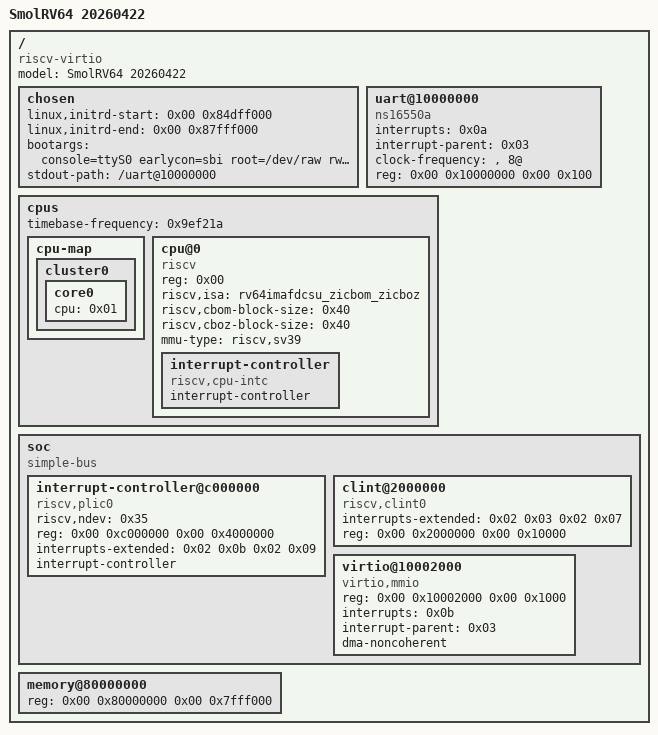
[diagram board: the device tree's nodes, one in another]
/dts-v1/;

/ {
	#address-cells = <0x02>;
	#size-cells = <0x02>;
	compatible = "riscv-virtio";
	model = "SmolRV64 20260422";

	chosen {
		linux,initrd-start = <0x00 0x84dff000>;
		linux,initrd-end = <0x00 0x87fff000>;
		bootargs = "console=ttyS0 earlycon=sbi root=/dev/raw rw ignore_loglevel";
		stdout-path = "/uart@10000000";
	};

	uart@10000000 {
		interrupts = <0x0a>;
		interrupt-parent = <0x03>;
		clock-frequency = "", "8@";
		reg = <0x00 0x10000000 0x00 0x100>;
		compatible = "ns16550a";
	};

	cpus {
		#address-cells = <0x01>;
		#size-cells = <0x00>;
		timebase-frequency = <0x9ef21a>;

		cpu-map {

			cluster0 {

				core0 {
					cpu = <0x01>;
				};
			};
		};

		cpu@0 {
			phandle = <0x01>;
			device_type = "cpu";
			reg = <0x00>;
			status = "okay";
			compatible = "riscv";
			riscv,isa = "rv64imafdcsu_zicbom_zicboz";
			riscv,cbom-block-size = <0x40>;
			riscv,cboz-block-size = <0x40>;
			mmu-type = "riscv,sv39";

			interrupt-controller {
				#interrupt-cells = <0x01>;
				interrupt-controller;
				compatible = "riscv,cpu-intc";
				phandle = <0x02>;
			};
		};
	};

	soc {
		#address-cells = <0x02>;
		#size-cells = <0x02>;
		compatible = "simple-bus";
		ranges;

		interrupt-controller@c000000 {
			phandle = <0x03>;
			riscv,ndev = <0x35>;
			reg = <0x00 0xc000000 0x00 0x4000000>;
			interrupts-extended = <0x02 0x0b 0x02 0x09>;
			interrupt-controller;
			compatible = "riscv,plic0";
			#interrupt-cells = <0x01>;
			#address-cells = <0x00>;
		};

		clint@2000000 {
			interrupts-extended = <0x02 0x03 0x02 0x07>;
			reg = <0x00 0x2000000 0x00 0x10000>;
			compatible = "riscv,clint0";
		};

		virtio@10002000 {
			compatible = "virtio,mmio";
			reg = <0x00 0x10002000 0x00 0x1000>;
			interrupts = <0x0b>;
			interrupt-parent = <0x03>;
			dma-noncoherent;
			status = "okay";
		};
	};

	memory@80000000 {
		device_type = "memory";
		reg = <0x00 0x80000000 0x00 0x7fff000>;
	};
};
